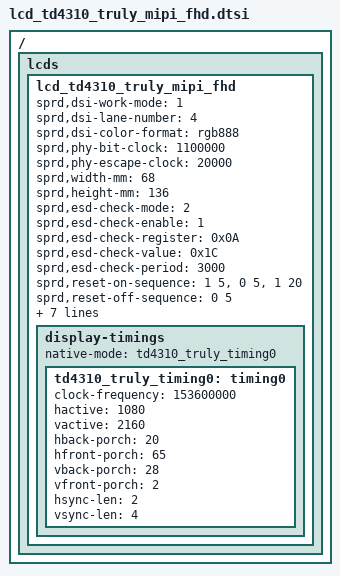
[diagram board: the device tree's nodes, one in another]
// SPDX-License-Identifier: GPL-2.0-only
/*
 * Unisoc Td4310 Truly LCD config DTS file
 *
 * Copyright (C) 2021, Unisoc Inc.
 */
/ {
	fragment {
		target-path = "/";
		__overlay__ {
			lcds {
				lcd_td4310_truly_mipi_fhd: lcd_td4310_truly_mipi_fhd {

					sprd,dsi-work-mode = <1>; /* video burst mode*/
					sprd,dsi-lane-number = <4>;
					sprd,dsi-color-format = "rgb888";

					sprd,phy-bit-clock = <1100000>;  /* kbps */
					sprd,phy-escape-clock = <20000>; /* kHz */

					sprd,width-mm = <68>;
					sprd,height-mm = <136>;

					sprd,esd-check-mode = <2>;
					sprd,esd-check-enable = <1>;
					sprd,esd-check-register = <0x0A>;
					sprd,esd-check-value = <0x1C>;
					sprd,esd-check-period = <3000>;

					sprd,reset-on-sequence = <1 5>, <0 5>, <1 20>;
					sprd,reset-off-sequence = <0 5>;

					sprd,use-dcs-write;

					sprd,initial-command = [
						39 00 00 02 b0 00
						39 00 00 04 B3 31 00 06
						39 00 00 02 b4 00
						39 00 00 06 B6 33 5B 81 72 00
						39 00 00 08 B8 57 3D 19 1E 0A 50 50
						39 00 00 08 B9 6F 3D 28 3C 14 C8 C8
						39 00 00 08 BA B5 33 41 64 23 A0 A0
						39 00 00 03 BB 14 14
						39 00 00 03 BC 37 32
						39 00 00 03 BD 64 32
						39 00 00 02 BE 04
						39 00 00 02 C0 00
						39 00 00 31 C1 04 40 00 00 26 15 19 0B 63 D2 D9 9A
							73 EF BD E7 5C 6B 93 4D 22 18 8B 2A 41 00
							00 00 00 00 00 00 00 00 40 02 22 1B 06 03
							00 0F FF 00 01 00 00 00
						39 00 00 19 C2 01 F8 70 08 68 08 0C 10 00 08 30 00
							00 00 00 00 00 00 00 08 00 00 00 00
						39 00 00 3f C3 86 D8 6D 86 D0 00 00 00 00 00 44 24
							42 00 00 48 84 88 00 00 01 01 03 28 00 01
							00 01 00 00 19 00 19 00 00 00 19 00 19 00
							00 00 00 00 00 00 00 00 32 00 32 00 5A 02
							00 00 00 00 00 00 40 00
						39 00 00 15 C4 70 00 00 00 11 11 00 00 00 02 02 31
							01 00 00 00 02 01 01 01
						39 00 00 09 C5 08 00 00 00 00 70 00 00
						39 00 00 40 C6 42 21 21 05 3D 05 3D 01 02 01 02 05
							05 00 00 05 05 0B 0C 05 42 00 6E 61 00 00
							00 00 00 00 00 00 00 00 00 00 00 00 00 00
							00 00 00 00 00 00 00 00 00 00 00 00 00 00
							00 00 00 00 00 00 00 00 00
						39 00 00 27 C7 00 1F 30 43 52 5C 72 80 8B 95 45 4F
							5C 70 79 85 90 93 BF 00 1F 30 43 52 5C 72
							80 8B 95 45 4F 5C 70 79 85 90 93 BF
						39 00 00 38 C8 00 00 00 00 00 FC 00 00 00 00 00 FC
							00 00 00 00 00 FC 00 00 00 00 00 FC 00 00
							00 00 00 FC 00 00 00 00 00 FC 00 00 00 00
							00 FC 00 00 00 00 00 FC 00 00 00 00 00 FC 00
						39 00 00 14 C9 00 00 00 00 00 FC 00 00 00 00 00 FC
							00 00 00 00 00 FC 00
						39 00 00 2c CA 1C FC FC FC 00 00 00 00 00 00 00 00
							00 00 00 00 00 00 00 00 00 00 00 00 00 00
							00 00 00 00 00 00 00 00 00 00 00 00 00 00
							00 00 00
						39 00 00 1c CB FF FF FF FF 0F 00 08 00 01 00 31 F0
							40 08 00 00 00 00 00 00 00 00 00 00 00 00 00
						39 00 00 03 CC 02 01
						39 00 00 27 CD 25 00 28 00 28 00 5C 02 DF DF E0 E0
							D6 D6 E0 E0 01 00 00 00 32 00 32 00 5D 02
							24 24 01 33 00 33 00 5E 02 24 24 A2
						39 00 00 1a CE 5D 40 49 53 59 5E 63 68 6E 74 7E 8A
							98 A8 BB D0 FF 04 00 04 04 42 00 69 5A
						39 00 00 03 CF 4A 1D
						39 00 00 14 D0 33 57 D4 31 01 10 10 10 19 19 00 00
							00 00 00 00 00 6D 65
						39 00 00 02 d1 00
						39 00 00 16 D3 1B 3B BB 77 77 77 BB B3 33 00 00 6D
							6E C7 C7 33 BB F2 FD C6 0B
						39 00 00 0b D5 03 00 00 02 0E 02 0E 01 00 00
						39 00 00 02 d6 01
						39 00 00 22 D7 F6 FF 03 05 41 24 80 1F C7 1F 1B 00
							0C 07 20 00 00 00 00 00 0C 00 1F 00 FC 00
							00 AB 67 7E 5D 26 00
						39 00 00 08 D9 00 16 14 3F 0F 57 04
						39 00 00 05 DD 30 06 23 65
						39 00 00 05 DE 00 3F FF 90
						39 00 00 02 ea 1f
						39 00 00 04 EE 41 51 00
						39 00 00 04 F1 00 00 00
						15 00 00 02 35 00
						05 14 00 01 29
						05 64 00 01 11
						];

					sprd,sleep-in-command = [
						13 0A 00 01 28
						13 78 00 01 10
						];
					sprd,sleep-out-command = [
						13 78 00 01 11
						13 32 00 01 29
						];

					display-timings {
						native-mode = <&td4310_truly_timing0>;

						td4310_truly_timing0: timing0 {
							clock-frequency = <153600000>;
							hactive = <1080>;
							vactive = <2160>;
							hback-porch = <20>;
							hfront-porch = <65>;
							vback-porch = <28>;
							vfront-porch = <2>;
							hsync-len = <2>;
							vsync-len = <4>;
						};
					};
				};
			};
		};
	};
};
